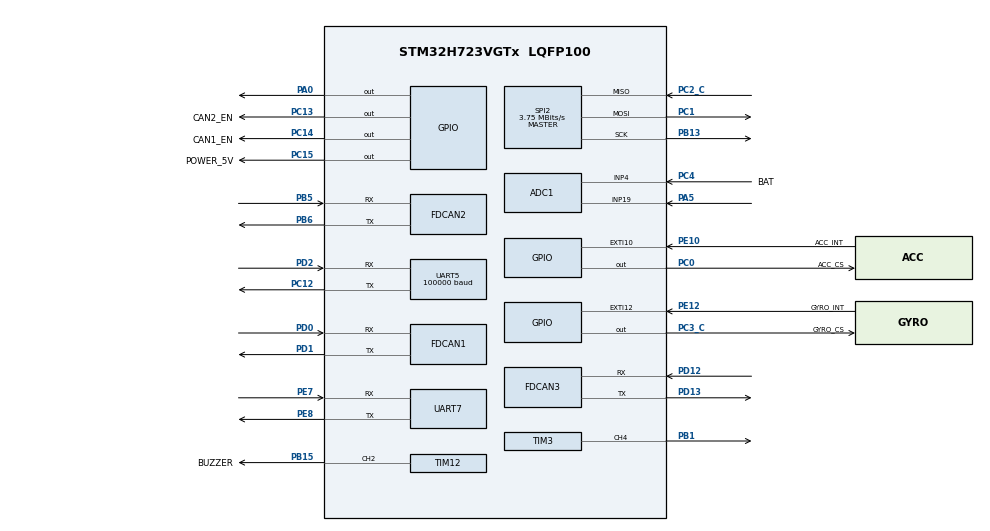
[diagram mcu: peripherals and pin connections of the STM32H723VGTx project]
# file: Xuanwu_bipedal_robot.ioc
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ADC1.Channel-0\#ChannelRegularConversion=ADC_CHANNEL_4
ADC1.Channel-1\#ChannelRegularConversion=ADC_CHANNEL_19
ADC1.ClockPrescaler=ADC_CLOCK_ASYNC_DIV64
ADC1.ContinuousConvMode=ENABLE
ADC1.ConversionDataManagement=ADC_CONVERSIONDATA_DMA_CIRCULAR
ADC1.NbrOfConversion=2
ADC1.NbrOfConversionFlag=1
ADC1.OffsetNumber-0\#ChannelRegularConversion=ADC_OFFSET_NONE
ADC1.OffsetNumber-1\#ChannelRegularConversion=ADC_OFFSET_NONE
ADC1.OffsetSignedSaturation-0\#ChannelRegularConversion=DISABLE
ADC1.OffsetSignedSaturation-1\#ChannelRegularConversion=DISABLE
ADC1.Rank-0\#ChannelRegularConversion=1
ADC1.Rank-1\#ChannelRegularConversion=2
ADC1.Ratio=1
ADC1.SamplingTime-0\#ChannelRegularConversion=ADC_SAMPLETIME_32CYCLES_5
ADC1.SamplingTime-1\#ChannelRegularConversion=ADC_SAMPLETIME_32CYCLES_5
ADC1.master=1
CORTEX_M7.Enable_Spec=__NULL
CORTEX_M7.default_mode_Activation=0
Dma.ADC1.3.Direction=DMA_PERIPH_TO_MEMORY
Dma.ADC1.3.EventEnable=DISABLE
Dma.ADC1.3.FIFOMode=DMA_FIFOMODE_DISABLE
Dma.ADC1.3.Instance=DMA1_Stream0
Dma.ADC1.3.MemDataAlignment=DMA_MDATAALIGN_HALFWORD
Dma.ADC1.3.MemInc=DMA_MINC_ENABLE
Dma.ADC1.3.Mode=DMA_CIRCULAR
Dma.ADC1.3.PeriphDataAlignment=DMA_PDATAALIGN_HALFWORD
Dma.ADC1.3.PeriphInc=DMA_PINC_DISABLE
Dma.ADC1.3.Polarity=HAL_DMAMUX_REQ_GEN_RISING
Dma.ADC1.3.Priority=DMA_PRIORITY_LOW
Dma.ADC1.3.RequestNumber=1
Dma.ADC1.3.SignalID=NONE
Dma.ADC1.3.SyncEnable=DISABLE
Dma.ADC1.3.SyncPolarity=HAL_DMAMUX_SYNC_NO_EVENT
Dma.ADC1.3.SyncRequestNumber=1
Dma.ADC1.3.SyncSignalID=NONE
Dma.Request0=SPI2_RX
Dma.Request1=SPI2_TX
Dma.Request2=UART5_RX
Dma.Request3=ADC1
Dma.SPI2_RX.0.Direction=DMA_PERIPH_TO_MEMORY
Dma.SPI2_RX.0.EventEnable=DISABLE
Dma.SPI2_RX.0.FIFOMode=DMA_FIFOMODE_DISABLE
Dma.SPI2_RX.0.Instance=DMA1_Stream3
Dma.SPI2_RX.0.MemDataAlignment=DMA_MDATAALIGN_BYTE
Dma.SPI2_RX.0.MemInc=DMA_MINC_ENABLE
Dma.SPI2_RX.0.Mode=DMA_NORMAL
Dma.SPI2_RX.0.PeriphDataAlignment=DMA_PDATAALIGN_BYTE
Dma.SPI2_RX.0.PeriphInc=DMA_PINC_DISABLE
Dma.SPI2_RX.0.Polarity=HAL_DMAMUX_REQ_GEN_RISING
Dma.SPI2_RX.0.Priority=DMA_PRIORITY_VERY_HIGH
Dma.SPI2_RX.0.RequestNumber=1
Dma.SPI2_RX.0.SignalID=NONE
Dma.SPI2_RX.0.SyncEnable=DISABLE
Dma.SPI2_RX.0.SyncPolarity=HAL_DMAMUX_SYNC_NO_EVENT
Dma.SPI2_RX.0.SyncRequestNumber=1
Dma.SPI2_RX.0.SyncSignalID=NONE
Dma.SPI2_TX.1.Direction=DMA_MEMORY_TO_PERIPH
Dma.SPI2_TX.1.EventEnable=DISABLE
Dma.SPI2_TX.1.FIFOMode=DMA_FIFOMODE_DISABLE
Dma.SPI2_TX.1.Instance=DMA1_Stream1
Dma.SPI2_TX.1.MemDataAlignment=DMA_MDATAALIGN_BYTE
Dma.SPI2_TX.1.MemInc=DMA_MINC_ENABLE
Dma.SPI2_TX.1.Mode=DMA_NORMAL
Dma.SPI2_TX.1.PeriphDataAlignment=DMA_PDATAALIGN_BYTE
Dma.SPI2_TX.1.PeriphInc=DMA_PINC_DISABLE
Dma.SPI2_TX.1.Polarity=HAL_DMAMUX_REQ_GEN_RISING
Dma.SPI2_TX.1.Priority=DMA_PRIORITY_HIGH
Dma.SPI2_TX.1.RequestNumber=1
Dma.SPI2_TX.1.SignalID=NONE
Dma.SPI2_TX.1.SyncEnable=DISABLE
Dma.SPI2_TX.1.SyncPolarity=HAL_DMAMUX_SYNC_NO_EVENT
Dma.SPI2_TX.1.SyncRequestNumber=1
Dma.SPI2_TX.1.SyncSignalID=NONE
Dma.UART5_RX.2.Direction=DMA_PERIPH_TO_MEMORY
Dma.UART5_RX.2.EventEnable=DISABLE
Dma.UART5_RX.2.FIFOMode=DMA_FIFOMODE_DISABLE
Dma.UART5_RX.2.Instance=DMA1_Stream2
Dma.UART5_RX.2.MemDataAlignment=DMA_MDATAALIGN_BYTE
Dma.UART5_RX.2.MemInc=DMA_MINC_ENABLE
Dma.UART5_RX.2.Mode=DMA_NORMAL
Dma.UART5_RX.2.PeriphDataAlignment=DMA_PDATAALIGN_BYTE
Dma.UART5_RX.2.PeriphInc=DMA_PINC_DISABLE
Dma.UART5_RX.2.Polarity=HAL_DMAMUX_REQ_GEN_RISING
Dma.UART5_RX.2.Priority=DMA_PRIORITY_VERY_HIGH
Dma.UART5_RX.2.RequestNumber=1
Dma.UART5_RX.2.SignalID=NONE
Dma.UART5_RX.2.SyncEnable=DISABLE
Dma.UART5_RX.2.SyncPolarity=HAL_DMAMUX_SYNC_NO_EVENT
Dma.UART5_RX.2.SyncRequestNumber=1
Dma.UART5_RX.2.SyncSignalID=NONE
FDCAN1.CalculateBaudRateNominal=1000000
FDCAN1.CalculateTimeBitNominal=1000
FDCAN1.CalculateTimeQuantumNominal=200.0
FDCAN1.NominalPrescaler=24
FDCAN1.RxFifo0ElmtsNbr=32
FDCAN1.StdFiltersNbr=1
FDCAN1.TxFifoQueueElmtsNbr=32
FDCAN2.CalculateBaudRateNominal=1000000
FDCAN2.CalculateTimeBitNominal=1000
FDCAN2.CalculateTimeQuantumNominal=200.0
FDCAN2.MessageRAMOffset=850
FDCAN2.NominalPrescaler=24
FDCAN2.RxFifo0ElmtsNbr=32
FDCAN2.StdFiltersNbr=1
FDCAN2.TxFifoQueueElmtsNbr=32
FDCAN3.AutoRetransmission=DISABLE
FDCAN3.CalculateBaudRateNominal=1000000
FDCAN3.CalculateTimeBitNominal=1000
FDCAN3.CalculateTimeQuantumNominal=200.0
FDCAN3.FrameFormat=FDCAN_FRAME_CLASSIC
FDCAN3.MessageRAMOffset=1700
FDCAN3.NominalPrescaler=24
FDCAN3.NominalTimeSeg1=2
FDCAN3.RxFifo0ElmtsNbr=32
FDCAN3.StdFiltersNbr=1
FDCAN3.TxFifoQueueElmtsNbr=32
FREERTOS.INCLUDE_vTaskDelayUntil=1
FREERTOS.Tasks01=Debug,24,256,Debug_Task,As weak,NULL,Dynamic,NULL,NULL;IMU,40,512,IMU_Task,As weak,NULL,Static,IMUBuffer,IMUControlBlock;Robot,40,256,Robot_Task,As weak,NULL,Dynamic,NULL,NULL;Motor_Ctrl,40,256,Motor_Ctrl_Task,As weak,NULL,Dynamic,NULL,NULL;System_Monitor,32,128,System_Monitor_Task,As weak,NULL,Dynamic,NULL,NULL;Orin,40,256,Orin_Task,As weak,NULL,Dynamic,NULL,NULL
FREERTOS.configGENERATE_RUN_TIME_STATS=1
FREERTOS.configUSE_STATS_FORMATTING_FUNCTIONS=1
FREERTOS.configUSE_TRACE_FACILITY=1
Mcu.Family=STM32H7
Mcu.Name=STM32H723VGTx
Mcu.Package=LQFP100
NVIC.DMA1_Stream0_IRQn=true\:6\:0\:true\:false\:true\:false\:true\:true\:true
NVIC.DMA1_Stream1_IRQn=true\:6\:0\:true\:false\:true\:false\:true\:true\:true
NVIC.DMA1_Stream2_IRQn=true\:5\:0\:false\:false\:true\:false\:true\:true\:true
NVIC.DMA1_Stream3_IRQn=true\:5\:0\:false\:false\:true\:true\:false\:true\:true
NVIC.EXTI15_10_IRQn=true\:6\:0\:true\:false\:true\:true\:true\:true\:true
NVIC.FDCAN1_IT0_IRQn=true\:5\:0\:false\:false\:true\:true\:true\:true\:true
NVIC.FDCAN1_IT1_IRQn=true\:5\:0\:false\:false\:true\:true\:true\:true\:true
NVIC.FDCAN2_IT0_IRQn=true\:5\:0\:false\:false\:true\:true\:true\:true\:true
NVIC.FDCAN2_IT1_IRQn=true\:5\:0\:false\:false\:true\:true\:true\:true\:true
NVIC.FDCAN3_IT0_IRQn=true\:5\:0\:false\:false\:true\:true\:true\:true\:true
NVIC.FDCAN3_IT1_IRQn=true\:5\:0\:false\:false\:true\:true\:true\:true\:true
NVIC.PriorityGroup=NVIC_PRIORITYGROUP_4
NVIC.SPI2_IRQn=true\:6\:0\:true\:false\:true\:false\:true\:true\:true
NVIC.TIM1_UP_IRQn=true\:15\:0\:false\:false\:true\:false\:true\:true\:true
NVIC.TimeBase=TIM1_UP_IRQn
NVIC.TimeBaseIP=TIM1
NVIC.UART5_IRQn=true\:5\:0\:false\:false\:true\:true\:true\:true\:true
PA0.GPIO_Speed=GPIO_SPEED_FREQ_VERY_HIGH
PA0.PinState=GPIO_PIN_RESET
PA0.Signal=GPIO_Output
PA13(JTMS/SWDIO).Mode=Serial_Wire
PA13(JTMS/SWDIO).Signal=DEBUG_JTMS-SWDIO
PA14(JTCK/SWCLK).Mode=Serial_Wire
PA14(JTCK/SWCLK).Signal=DEBUG_JTCK-SWCLK
PA5.Signal=ADCx_INP19
PB1.Signal=S_TIM3_CH4
PB13.GPIO_Speed=GPIO_SPEED_FREQ_VERY_HIGH
PB13.Mode=Full_Duplex_Master
PB13.Signal=SPI2_SCK
PB15.GPIO_Label=BUZZER
PB15.Signal=S_TIM12_CH2
PB5.Mode=FDCAN_Activate
PB5.Signal=FDCAN2_RX
PB6.Mode=FDCAN_Activate
PB6.Signal=FDCAN2_TX
PC0.GPIO_Label=ACC_CS
PC0.GPIO_Speed=GPIO_SPEED_FREQ_VERY_HIGH
PC0.PinState=GPIO_PIN_SET
PC0.Signal=GPIO_Output
PC1.GPIO_Speed=GPIO_SPEED_FREQ_VERY_HIGH
PC1.Mode=Full_Duplex_Master
PC1.Signal=SPI2_MOSI
PC12.GPIO_Speed=GPIO_SPEED_FREQ_LOW
PC12.Mode=Asynchronous
PC12.Signal=UART5_TX
PC13.GPIO_Label=CAN2_EN
PC13.Signal=GPIO_Output
PC14-OSC32_IN.GPIO_Label=CAN1_EN
PC14-OSC32_IN.Signal=GPIO_Output
PC15-OSC32_OUT.GPIO_Label=POWER_5V
PC15-OSC32_OUT.PinState=GPIO_PIN_SET
PC15-OSC32_OUT.Signal=GPIO_Output
PC2_C.GPIO_Speed=GPIO_SPEED_FREQ_VERY_HIGH
PC2_C.Mode=Full_Duplex_Master
PC2_C.Signal=SPI2_MISO
PC3_C.GPIO_Label=GYRO_CS
PC3_C.GPIO_Speed=GPIO_SPEED_FREQ_VERY_HIGH
PC3_C.PinState=GPIO_PIN_SET
PC3_C.Signal=GPIO_Output
PC4.GPIO_Label=BAT
PC4.Signal=ADCx_INP4
PD0.Mode=FDCAN_Activate
PD0.Signal=FDCAN1_RX
PD1.Mode=FDCAN_Activate
PD1.Signal=FDCAN1_TX
PD12.Mode=FDCAN_Activate
PD12.Signal=FDCAN3_RX
PD13.Mode=FDCAN_Activate
PD13.Signal=FDCAN3_TX
PD2.GPIO_Speed=GPIO_SPEED_FREQ_VERY_HIGH
PD2.Mode=Asynchronous
PD2.Signal=UART5_RX
PE10.GPIO_Label=ACC_INT
PE10.Signal=GPXTI10
PE12.GPIO_Label=GYRO_INT
PE12.Signal=GPXTI12
PE7.Mode=Asynchronous
PE7.Signal=UART7_RX
PE8.Mode=Asynchronous
PE8.Signal=UART7_TX
PH0-OSC_IN.Mode=HSE-External-Oscillator
PH0-OSC_IN.Signal=RCC_OSC_IN
PH1-OSC_OUT.Mode=HSE-External-Oscillator
PH1-OSC_OUT.Signal=RCC_OSC_OUT
ProjectManager.HeapSize=0x200
ProjectManager.StackSize=0x400
ProjectManager.TargetToolchain=MDK-ARM V5.27
RCC.ADCFreq_Value=96000000
RCC.APB1Freq_Value=120000000
RCC.APB2Freq_Value=120000000
RCC.APB3Freq_Value=120000000
RCC.APB4Freq_Value=120000000
RCC.CortexFreq_Value=480000000
RCC.D1PPRE=RCC_APB3_DIV2
RCC.D2PPRE1=RCC_APB1_DIV2
RCC.D2PPRE2=RCC_APB2_DIV2
RCC.D3PPRE=RCC_APB4_DIV2
RCC.DIVM1=2
RCC.DIVM2=2
RCC.DIVN1=40
RCC.DIVN2=16
RCC.DIVP1=1
RCC.DIVQ1=4
RCC.HCLKFreq_Value=240000000
RCC.HPRE=RCC_HCLK_DIV2
RCC.HSE_VALUE=24000000
RCC.PLL1_VCI_Range-AdvancedSettings=RCC_PLL1VCIRANGE_0
RCC.PLL1_VCO_SEL-AdvancedSettings=RCC_PLL1VCOMEDIUM
RCC.PLL2FRACN=0
RCC.PLL2_VCI_Range-AdvancedSettings=RCC_PLL2VCIRANGE_3
RCC.PLL2_VCO_SEL-AdvancedSettings=RCC_PLL2VCOWIDE
RCC.PLL3FRACN=0
RCC.PLLFRACN=0
RCC.PLLSourceVirtual=RCC_PLLSOURCE_HSE
RCC.SYSCLKFreq_VALUE=480000000
RCC.SYSCLKSource=RCC_SYSCLKSOURCE_PLLCLK
RCC.USBFreq_Value=120000000
SH.ADCx_INP19.0=ADC1_INP19,IN19-Single-Ended
SH.ADCx_INP4.0=ADC1_INP4,IN4-Single-Ended
SH.S_TIM12_CH2.0=TIM12_CH2,PWM Generation2 CH2
SH.S_TIM3_CH4.0=TIM3_CH4,PWM Generation4 CH4
SPI2.BaudRatePrescaler=SPI_BAUDRATEPRESCALER_32
SPI2.CLKPhase=SPI_PHASE_2EDGE
SPI2.CLKPolarity=SPI_POLARITY_HIGH
SPI2.CalculateBaudRate=3.75 MBits/s
SPI2.DataSize=SPI_DATASIZE_8BIT
SPI2.Direction=SPI_DIRECTION_2LINES
SPI2.Mode=SPI_MODE_MASTER
SPI2.VirtualType=VM_MASTER
TIM12.Channel-PWM\ Generation2\ CH2=TIM_CHANNEL_2
TIM12.Period=2000-1
TIM12.Prescaler=24-1
TIM12.Pulse-PWM\ Generation2\ CH2=1000
TIM3.AutoReloadPreload=TIM_AUTORELOAD_PRELOAD_ENABLE
TIM3.Channel-PWM\ Generation4\ CH4=TIM_CHANNEL_4
TIM3.Period=10000-1
TIM3.Prescaler=24-1
UART5.BaudRate=100000
UART5.Mode=MODE_RX
UART5.Parity=PARITY_EVEN
UART5.StopBits=UART_STOPBITS_2
UART5.WordLength=WORDLENGTH_9B
VP_FREERTOS_VS_CMSIS_V2.Mode=CMSIS_V2
VP_MEMORYMAP_VS_MEMORYMAP.Mode=CurAppReg
VP_SYS_VS_tim1.Mode=TIM1
VP_TIM3_VS_ClockSourceINT.Mode=Internal
board=custom

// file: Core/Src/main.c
/* USER CODE BEGIN Header */
/**
  ******************************************************************************
  * @file           : main.c
  * @brief          : Main program body
  ******************************************************************************
  * @attention
  *
  * Copyright (c) 2024 STMicroelectronics.
  * All rights reserved.
  *
  * This software is licensed under terms that can be found in the LICENSE file
  * in the root directory of this software component.
  * If no LICENSE file comes with this software, it is provided AS-IS.
  *
  ******************************************************************************
  */
/* USER CODE END Header */
#include "main.h"
#include "cmsis_os.h"
#include "adc.h"
#include "dma.h"
#include "fdcan.h"
#include "memorymap.h"
#include "spi.h"
#include "tim.h"
#include "usart.h"
#include "gpio.h"

/* USER CODE BEGIN Includes */
#include "BMI088driver.h"
#include "FreeRTOS.h"
#include "task.h"
/* USER CODE END Includes */

void SystemClock_Config(void);
void MX_FREERTOS_Init(void);

int main(void)
{

  /* MCU Configuration--------------------------------------------------------*/

  /* Reset of all peripherals, Initializes the Flash interface and the Systick. */
  HAL_Init();

  /* Configure the system clock */
  SystemClock_Config();

  /* Initialize all configured peripherals */
  MX_GPIO_Init();
  MX_DMA_Init();
  MX_SPI2_Init();
  MX_TIM3_Init();
  MX_UART7_Init();
  MX_UART5_Init();
  MX_FDCAN1_Init();
  MX_FDCAN2_Init();
  MX_ADC1_Init();
  MX_TIM12_Init();
  MX_FDCAN3_Init();

  /* Init scheduler */
  osKernelInitialize();

  /* Call init function for freertos objects (in cmsis_os2.c) */
  MX_FREERTOS_Init();

  /* Start scheduler */
  osKernelStart();

  /* We should never get here as control is now taken by the scheduler */

  /* Infinite loop */
  while (1)
  {

  }
}

void SystemClock_Config(void)
{
  RCC_OscInitTypeDef RCC_OscInitStruct = {0};
  RCC_ClkInitTypeDef RCC_ClkInitStruct = {0};

  /** Supply configuration update enable
  */
  HAL_PWREx_ConfigSupply(PWR_LDO_SUPPLY);

  /** Configure the main internal regulator output voltage
  */
  __HAL_PWR_VOLTAGESCALING_CONFIG(PWR_REGULATOR_VOLTAGE_SCALE0);

  while(!__HAL_PWR_GET_FLAG(PWR_FLAG_VOSRDY)) {}

  /** Initializes the RCC Oscillators according to the specified parameters
  * in the RCC_OscInitTypeDef structure.
  */
  RCC_OscInitStruct.OscillatorType = RCC_OSCILLATORTYPE_HSE;
  RCC_OscInitStruct.HSEState = RCC_HSE_ON;
  RCC_OscInitStruct.PLL.PLLState = RCC_PLL_ON;
  RCC_OscInitStruct.PLL.PLLSource = RCC_PLLSOURCE_HSE;
  RCC_OscInitStruct.PLL.PLLM = 2;
  RCC_OscInitStruct.PLL.PLLN = 40;
  RCC_OscInitStruct.PLL.PLLP = 1;
  RCC_OscInitStruct.PLL.PLLQ = 4;
  RCC_OscInitStruct.PLL.PLLR = 2;
  RCC_OscInitStruct.PLL.PLLRGE = RCC_PLL1VCIRANGE_3;
  RCC_OscInitStruct.PLL.PLLVCOSEL = RCC_PLL1VCOWIDE;
  RCC_OscInitStruct.PLL.PLLFRACN = 0;
  if (HAL_RCC_OscConfig(&RCC_OscInitStruct) != HAL_OK)
  {
    Error_Handler();
  }

  /** Initializes the CPU, AHB and APB buses clocks
  */
  RCC_ClkInitStruct.ClockType = RCC_CLOCKTYPE_HCLK|RCC_CLOCKTYPE_SYSCLK
                              |RCC_CLOCKTYPE_PCLK1|RCC_CLOCKTYPE_PCLK2
                              |RCC_CLOCKTYPE_D3PCLK1|RCC_CLOCKTYPE_D1PCLK1;
  RCC_ClkInitStruct.SYSCLKSource = RCC_SYSCLKSOURCE_PLLCLK;
  RCC_ClkInitStruct.SYSCLKDivider = RCC_SYSCLK_DIV1;
  RCC_ClkInitStruct.AHBCLKDivider = RCC_HCLK_DIV2;
  RCC_ClkInitStruct.APB3CLKDivider = RCC_APB3_DIV2;
  RCC_ClkInitStruct.APB1CLKDivider = RCC_APB1_DIV2;
  RCC_ClkInitStruct.APB2CLKDivider = RCC_APB2_DIV2;
  RCC_ClkInitStruct.APB4CLKDivider = RCC_APB4_DIV2;

  if (HAL_RCC_ClockConfig(&RCC_ClkInitStruct, FLASH_LATENCY_3) != HAL_OK)
  {
    Error_Handler();
  }
}

void HAL_TIM_PeriodElapsedCallback(TIM_HandleTypeDef *htim)
{
  if (htim->Instance == TIM1) {
    HAL_IncTick();
  }
}

void Error_Handler(void)
{
  __disable_irq();
  while (1)
  {
  }
}

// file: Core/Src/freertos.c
/* USER CODE BEGIN Header */
/**
  ******************************************************************************
  * File Name          : freertos.c
  * Description        : Code for freertos applications
  ******************************************************************************
  * @attention
  *
  * Copyright (c) 2024 STMicroelectronics.
  * All rights reserved.
  *
  * This software is licensed under terms that can be found in the LICENSE file
  * in the root directory of this software component.
  * If no LICENSE file comes with this software, it is provided AS-IS.
  *
  ******************************************************************************
  */
/* USER CODE END Header */

#include "FreeRTOS.h"
#include "task.h"
#include "main.h"
#include "cmsis_os.h"

/* USER CODE BEGIN Includes */
#include "Task_Manager.h"
/* USER CODE END Includes */

typedef StaticTask_t osStaticThreadDef_t;

/* USER CODE BEGIN Variables */
osSemaphoreId imuBinarySem01Handle;
StaticSemaphore_t  imuBinarySemControlBlock;
/* USER CODE END Variables */
/* Definitions for Debug */
osThreadId_t DebugHandle;
const osThreadAttr_t Debug_attributes = {
  .name = "Debug",
  .stack_size = 256 * 4,
  .priority = (osPriority_t) osPriorityHigh,
};
/* Definitions for IMU */
osThreadId_t IMUHandle;
uint32_t IMUBuffer[ 512 ];
osStaticThreadDef_t IMUControlBlock;
const osThreadAttr_t IMU_attributes = {
  .name = "IMU",
  .cb_mem = &IMUControlBlock,
  .cb_size = sizeof(IMUControlBlock),
  .stack_mem = &IMUBuffer[0],
  .stack_size = sizeof(IMUBuffer),
  .priority = (osPriority_t) osPriorityHigh,
};
/* Definitions for Robot */
osThreadId_t RobotHandle;
const osThreadAttr_t Robot_attributes = {
  .name = "Robot",
  .stack_size = 256 * 4,
  .priority = (osPriority_t) osPriorityHigh,
};
/* Definitions for Motor_Ctrl */
osThreadId_t Motor_CtrlHandle;
const osThreadAttr_t Motor_Ctrl_attributes = {
  .name = "Motor_Ctrl",
  .stack_size = 256 * 4,
  .priority = (osPriority_t) osPriorityHigh,
};
/* Definitions for System_Monitor */
osThreadId_t System_MonitorHandle;
const osThreadAttr_t System_Monitor_attributes = {
  .name = "System_Monitor",
  .stack_size = 128 * 4,
  .priority = (osPriority_t) osPriorityHigh,
};
/* Definitions for Orin */
osThreadId_t OrinHandle;
const osThreadAttr_t Orin_attributes = {
  .name = "Orin",
  .stack_size = 256 * 4,
  .priority = (osPriority_t) osPriorityHigh,
};

void Debug_Task(void *argument);
void IMU_Task(void *argument);
void Robot_Task(void *argument);
void Motor_Ctrl_Task(void *argument);
void System_Monitor_Task(void *argument);
void Orin_Task(void *argument);

void MX_FREERTOS_Init(void); /* (MISRA C 2004 rule 8.1) */

/* Hook prototypes */
void configureTimerForRunTimeStats(void);
unsigned long getRunTimeCounterValue(void);

/* USER CODE BEGIN 1 */
/* Functions needed when configGENERATE_RUN_TIME_STATS is on */
__weak void configureTimerForRunTimeStats(void)
{

}

__weak unsigned long getRunTimeCounterValue(void)
{
return 0;
}
/* USER CODE END 1 */

void MX_FREERTOS_Init(void) {

  /* USER CODE BEGIN RTOS_SEMAPHORES */
  /* definition and creation of imuBinarySem01 */
  const osSemaphoreAttr_t imuBinarySem01_attributes = {
    .name = "imuBinarySem01",
    .cb_mem = &imuBinarySemControlBlock,       // Pointer to the static control block
    .cb_size = sizeof(imuBinarySemControlBlock) // Size of the control block
	};
	osSemaphoreId_t imuBinarySem01Handle = osSemaphoreNew(1, 1, &imuBinarySem01_attributes);
  /* USER CODE END RTOS_SEMAPHORES */

  /* Create the thread(s) */
  /* creation of Debug */
  DebugHandle = osThreadNew(Debug_Task, NULL, &Debug_attributes);

  /* creation of IMU */
  IMUHandle = osThreadNew(IMU_Task, NULL, &IMU_attributes);

  /* creation of Robot */
  RobotHandle = osThreadNew(Robot_Task, NULL, &Robot_attributes);

  /* creation of Motor_Ctrl */
  Motor_CtrlHandle = osThreadNew(Motor_Ctrl_Task, NULL, &Motor_Ctrl_attributes);

  /* creation of System_Monitor */
  System_MonitorHandle = osThreadNew(System_Monitor_Task, NULL, &System_Monitor_attributes);

  /* creation of Orin */
  OrinHandle = osThreadNew(Orin_Task, NULL, &Orin_attributes);

}

__weak void Debug_Task(void *argument)
{
  for(;;)
  {
    osDelay(1);
  }
}

__weak void IMU_Task(void *argument)
{
  for(;;)
  {
    osDelay(1);
  }
}

__weak void Robot_Task(void *argument)
{
  for(;;)
  {
    osDelay(1);
  }
}

__weak void Motor_Ctrl_Task(void *argument)
{
  for(;;)
  {
    osDelay(1);
  }
}

__weak void System_Monitor_Task(void *argument)
{
  for(;;)
  {
    osDelay(1);
  }
}

__weak void Orin_Task(void *argument)
{
  for(;;)
  {
    osDelay(1);
  }
}
